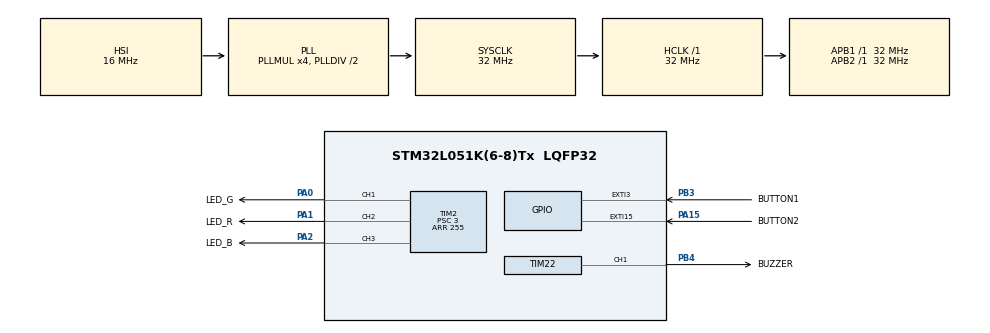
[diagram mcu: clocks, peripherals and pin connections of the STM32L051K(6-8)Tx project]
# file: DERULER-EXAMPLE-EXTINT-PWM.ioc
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Mcu.Family=STM32L0
Mcu.Name=STM32L051K(6-8)Tx
Mcu.Package=LQFP32
NVIC.EXTI2_3_IRQn=true\:0\:0\:false\:false\:true\:true\:true
NVIC.EXTI4_15_IRQn=true\:0\:0\:false\:false\:true\:true\:true
PA0.GPIO_Label=LED_G
PA0.Signal=S_TIM2_CH1
PA1.GPIO_Label=LED_R
PA1.Signal=S_TIM2_CH2
PA13.Mode=Serial_Wire
PA13.Signal=SYS_SWDIO
PA14.Mode=Serial_Wire
PA14.Signal=SYS_SWCLK
PA15.GPIO_Label=BUTTON2
PA15.GPIO_ModeDefaultEXTI=GPIO_MODE_IT_FALLING
PA15.GPIO_PuPd=GPIO_PULLUP
PA15.Signal=GPXTI15
PA2.GPIO_Label=LED_B
PA2.Signal=S_TIM2_CH3
PB3.GPIO_Label=BUTTON1
PB3.GPIO_ModeDefaultEXTI=GPIO_MODE_IT_FALLING
PB3.GPIO_PuPd=GPIO_PULLUP
PB3.Signal=GPXTI3
PB4.GPIO_Label=BUZZER
PB4.Signal=S_TIM22_CH1
ProjectManager.HeapSize=0x200
ProjectManager.StackSize=0x400
ProjectManager.TargetToolchain=STM32CubeIDE
RCC.AHBFreq_Value=32000000
RCC.APB1Freq_Value=32000000
RCC.APB1TimFreq_Value=32000000
RCC.APB2Freq_Value=32000000
RCC.APB2TimFreq_Value=32000000
RCC.HCLKFreq_Value=32000000
RCC.HSI16_VALUE=16000000
RCC.HSI_VALUE=16000000
RCC.LSE_VALUE=32768
RCC.MSI_VALUE=2097000
RCC.PLLMUL=RCC_PLLMUL_4
RCC.SYSCLKFreq_VALUE=32000000
RCC.SYSCLKSource=RCC_SYSCLKSOURCE_PLLCLK
RCC.VCOOutputFreq_Value=64000000
SH.S_TIM22_CH1.0=TIM22_CH1,PWM Generation1 CH1
SH.S_TIM2_CH1.0=TIM2_CH1,PWM Generation1 CH1
SH.S_TIM2_CH2.0=TIM2_CH2,PWM Generation2 CH2
SH.S_TIM2_CH3.0=TIM2_CH3,PWM Generation3 CH3
TIM2.Channel-PWM\ Generation1\ CH1=TIM_CHANNEL_1
TIM2.Channel-PWM\ Generation2\ CH2=TIM_CHANNEL_2
TIM2.Channel-PWM\ Generation3\ CH3=TIM_CHANNEL_3
TIM2.Period=255
TIM2.Prescaler=3
TIM22.Channel-PWM\ Generation1\ CH1=TIM_CHANNEL_1
TIM22.Period=99
TIM22.Prescaler=3199
TIM22.Pulse-PWM\ Generation1\ CH1=50
VP_TIM22_VS_ClockSourceINT.Mode=Internal
VP_TIM2_VS_ClockSourceINT.Mode=Internal
board=custom

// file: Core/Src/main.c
/* USER CODE BEGIN Header */
/**
  ******************************************************************************
  * @file           : main.c
  * @brief          : Main program body
  ******************************************************************************
  * @attention
  *
  * <h2><center>&copy; Copyright (c) 2021 STMicroelectronics.
  * All rights reserved.</center></h2>
  *
  * This software component is licensed by ST under BSD 3-Clause license,
  * the "License"; You may not use this file except in compliance with the
  * License. You may obtain a copy of the License at:
  *                        opensource.org/licenses/BSD-3-Clause
  *
  ******************************************************************************
  */

/**
 * DERULER-EXAMPLE-EXTINT-PWM (main.c)
 *
 * This examples shows how to use basic peripherals for external interrupts and pulse-width modulation (PWM) to improve our application.
 * Peripherals in a microcontroller are built-in hardware functions that can be used to off-load the processor. Instead of continuously reading
 * the value of the BUTTON1 and BUTTON2 pins in our code at some interval, we can get notified through an interrupt when the pin value has
 * changed due to the button being pressed. When an interrupt occurs the microcontroller will immediately stop working on what it was doing and
 * jump to the code we've written for what to do when the interrupt occurs. After this code has finished executing the microcontroller will go
 * back to doing what it was doing previously.
 *
 * By using the timer peripheral in PWM mode we can improve the RGB LED functionality by controlling the intensity of each color. This
 * lets us mix red, green and blue to create virtually any color.  In our application we set the timer to count from 0 to 255 (256 steps). Each
 * channel (color) can then be set to any value between 0-256 where 0 means fully off and 256 means fully on. With each color having 256
 * different intensities to select from we can create a total of 256 * 256 * 256 = 16.7M different colors. The 256 value is selected as it
 * represents 8 bits. This means we get 8-bit color per channel, or 24-bit total color information (8-bit * 3 colors, red + green + blue).
 * When BUTTON1 is pressed we start cycling between colors by adding or subtracting different amounts to the the different color. If the button
 * is pressed again we stop cycling the colors.
 *
 * In order to generate sound using the magnetic buzzer in our circuit we can also rely on a timer in PWM mode. By adjusting the timer
 * frequency and PWM duty cycle we can generate different sounds. In this example we configure the timer to generate a 100 Hz square wave signal
 * at 50% duty cycle which is activated when BUTTON2 is pressed. If the button is pressed again the frequency is doubled. If the frequency
 * reaches more than 20 KHz we stop the PWM output.
 *
 * Note1: The code for our main application is in this file (main.c). The code for handling interrupts is in stm32l0xx_it.c.
 * Note2: The audio frequenies we'll hear are: 100 Hz, 200 Hz, 400 Hz, 800 Hz, 1600 Hz, 3200 Hz, 6400 Hz, 12800 Hz
 *
 */

/* USER CODE END Header */
#include "main.h"

TIM_HandleTypeDef htim2;
TIM_HandleTypeDef htim22;

/* USER CODE BEGIN PV */

// RGB variables
int change_color = 0;
int red = 0;
int green = 0;
int blue = 0;
int red_add = 1;
int green_add = 2;
int blue_add = 3;

// Buzzer variables
int buzzer_active = 0;
int buzzer_frequency = 100;

/* USER CODE END PV */

void SystemClock_Config(void);
static void MX_GPIO_Init(void);
static void MX_TIM2_Init(void);
static void MX_TIM22_Init(void);

int main(void)
{

  /* MCU Configuration--------------------------------------------------------*/

  /* Reset of all peripherals, Initializes the Flash interface and the Systick. */
  HAL_Init();

  /* Configure the system clock */
  SystemClock_Config();

  /* Initialize all configured peripherals */
  MX_GPIO_Init();
  MX_TIM2_Init();
  MX_TIM22_Init();
  /* USER CODE BEGIN 2 */

  // Start PWM output of RGB LED channels
  HAL_TIM_PWM_Start(&htim2, TIM_CHANNEL_1);
  HAL_TIM_PWM_Start(&htim2, TIM_CHANNEL_2);
  HAL_TIM_PWM_Start(&htim2, TIM_CHANNEL_3);

  /* USER CODE END 2 */

  /* Infinite loop */
  while (1)
  {

	  // If change_color is 1, change color
	  if(change_color == 1) {

		  red += red_add; // Increase red by 1 each time, or decrease by 1 if max was reached
		  green += green_add; // Increase green by 2 each time, or decrease by 2 if max was reached
		  blue += blue_add; // Increase blue by 3 each time, or decrease by 3 if max was reached

		  // If any color value is more than 255 limit it to 256. If any color is less than 0, limit it to 0.
		  // Additionally change the sign of the value added to it each cycle to reverse the direction
		  if(red > 255) {
			  red = 256;
			  red_add = -red_add;
		  }
		  if(red < 0) {
			  red = 0;
			  red_add = -red_add;
		  }

		  if(green > 255) {
			  green = 256;
			  green_add = -green_add;
		  }
		  if(green < 0) {
			  green = 0;
			  green_add = -green_add;
		  }

		  if(blue > 255) {
			  blue = 256;
			  blue_add = -blue_add;
		  }
		  if(blue < 0) {
			  blue = 0;
			  blue_add = -blue_add;
		  }

		  // Apply color values to the corresponding PWM channel
		  __HAL_TIM_SET_COMPARE(&htim2, TIM_CHANNEL_2, red);
		  __HAL_TIM_SET_COMPARE(&htim2, TIM_CHANNEL_1, green);
		  __HAL_TIM_SET_COMPARE(&htim2, TIM_CHANNEL_3, blue);

		  // Wait for 10 ms before repeating
		  HAL_Delay(10);

	  }
  }
}

void SystemClock_Config(void)
{
  RCC_OscInitTypeDef RCC_OscInitStruct = {0};
  RCC_ClkInitTypeDef RCC_ClkInitStruct = {0};

  /** Configure the main internal regulator output voltage
  */
  __HAL_PWR_VOLTAGESCALING_CONFIG(PWR_REGULATOR_VOLTAGE_SCALE1);
  /** Initializes the RCC Oscillators according to the specified parameters
  * in the RCC_OscInitTypeDef structure.
  */
  RCC_OscInitStruct.OscillatorType = RCC_OSCILLATORTYPE_HSI;
  RCC_OscInitStruct.HSIState = RCC_HSI_ON;
  RCC_OscInitStruct.HSICalibrationValue = RCC_HSICALIBRATION_DEFAULT;
  RCC_OscInitStruct.PLL.PLLState = RCC_PLL_ON;
  RCC_OscInitStruct.PLL.PLLSource = RCC_PLLSOURCE_HSI;
  RCC_OscInitStruct.PLL.PLLMUL = RCC_PLLMUL_4;
  RCC_OscInitStruct.PLL.PLLDIV = RCC_PLLDIV_2;
  if (HAL_RCC_OscConfig(&RCC_OscInitStruct) != HAL_OK)
  {
    Error_Handler();
  }
  /** Initializes the CPU, AHB and APB buses clocks
  */
  RCC_ClkInitStruct.ClockType = RCC_CLOCKTYPE_HCLK|RCC_CLOCKTYPE_SYSCLK
                              |RCC_CLOCKTYPE_PCLK1|RCC_CLOCKTYPE_PCLK2;
  RCC_ClkInitStruct.SYSCLKSource = RCC_SYSCLKSOURCE_PLLCLK;
  RCC_ClkInitStruct.AHBCLKDivider = RCC_SYSCLK_DIV1;
  RCC_ClkInitStruct.APB1CLKDivider = RCC_HCLK_DIV1;
  RCC_ClkInitStruct.APB2CLKDivider = RCC_HCLK_DIV1;

  if (HAL_RCC_ClockConfig(&RCC_ClkInitStruct, FLASH_LATENCY_1) != HAL_OK)
  {
    Error_Handler();
  }
}

static void MX_TIM2_Init(void)
{

  TIM_ClockConfigTypeDef sClockSourceConfig = {0};
  TIM_MasterConfigTypeDef sMasterConfig = {0};
  TIM_OC_InitTypeDef sConfigOC = {0};

  htim2.Instance = TIM2;
  htim2.Init.Prescaler = 3;
  htim2.Init.CounterMode = TIM_COUNTERMODE_UP;
  htim2.Init.Period = 255;
  htim2.Init.ClockDivision = TIM_CLOCKDIVISION_DIV1;
  htim2.Init.AutoReloadPreload = TIM_AUTORELOAD_PRELOAD_DISABLE;
  if (HAL_TIM_Base_Init(&htim2) != HAL_OK)
  {
    Error_Handler();
  }
  sClockSourceConfig.ClockSource = TIM_CLOCKSOURCE_INTERNAL;
  if (HAL_TIM_ConfigClockSource(&htim2, &sClockSourceConfig) != HAL_OK)
  {
    Error_Handler();
  }
  if (HAL_TIM_PWM_Init(&htim2) != HAL_OK)
  {
    Error_Handler();
  }
  sMasterConfig.MasterOutputTrigger = TIM_TRGO_RESET;
  sMasterConfig.MasterSlaveMode = TIM_MASTERSLAVEMODE_DISABLE;
  if (HAL_TIMEx_MasterConfigSynchronization(&htim2, &sMasterConfig) != HAL_OK)
  {
    Error_Handler();
  }
  sConfigOC.OCMode = TIM_OCMODE_PWM1;
  sConfigOC.Pulse = 0;
  sConfigOC.OCPolarity = TIM_OCPOLARITY_HIGH;
  sConfigOC.OCFastMode = TIM_OCFAST_DISABLE;
  if (HAL_TIM_PWM_ConfigChannel(&htim2, &sConfigOC, TIM_CHANNEL_1) != HAL_OK)
  {
    Error_Handler();
  }
  if (HAL_TIM_PWM_ConfigChannel(&htim2, &sConfigOC, TIM_CHANNEL_2) != HAL_OK)
  {
    Error_Handler();
  }
  if (HAL_TIM_PWM_ConfigChannel(&htim2, &sConfigOC, TIM_CHANNEL_3) != HAL_OK)
  {
    Error_Handler();
  }
  HAL_TIM_MspPostInit(&htim2);

}

static void MX_TIM22_Init(void)
{

  TIM_ClockConfigTypeDef sClockSourceConfig = {0};
  TIM_MasterConfigTypeDef sMasterConfig = {0};
  TIM_OC_InitTypeDef sConfigOC = {0};

  htim22.Instance = TIM22;
  htim22.Init.Prescaler = 3199;
  htim22.Init.CounterMode = TIM_COUNTERMODE_UP;
  htim22.Init.Period = 99;
  htim22.Init.ClockDivision = TIM_CLOCKDIVISION_DIV1;
  htim22.Init.AutoReloadPreload = TIM_AUTORELOAD_PRELOAD_DISABLE;
  if (HAL_TIM_Base_Init(&htim22) != HAL_OK)
  {
    Error_Handler();
  }
  sClockSourceConfig.ClockSource = TIM_CLOCKSOURCE_INTERNAL;
  if (HAL_TIM_ConfigClockSource(&htim22, &sClockSourceConfig) != HAL_OK)
  {
    Error_Handler();
  }
  if (HAL_TIM_PWM_Init(&htim22) != HAL_OK)
  {
    Error_Handler();
  }
  sMasterConfig.MasterOutputTrigger = TIM_TRGO_RESET;
  sMasterConfig.MasterSlaveMode = TIM_MASTERSLAVEMODE_DISABLE;
  if (HAL_TIMEx_MasterConfigSynchronization(&htim22, &sMasterConfig) != HAL_OK)
  {
    Error_Handler();
  }
  sConfigOC.OCMode = TIM_OCMODE_PWM1;
  sConfigOC.Pulse = 50;
  sConfigOC.OCPolarity = TIM_OCPOLARITY_HIGH;
  sConfigOC.OCFastMode = TIM_OCFAST_DISABLE;
  if (HAL_TIM_PWM_ConfigChannel(&htim22, &sConfigOC, TIM_CHANNEL_1) != HAL_OK)
  {
    Error_Handler();
  }
  HAL_TIM_MspPostInit(&htim22);

}

static void MX_GPIO_Init(void)
{
  GPIO_InitTypeDef GPIO_InitStruct = {0};

  /* GPIO Ports Clock Enable */
  __HAL_RCC_GPIOA_CLK_ENABLE();
  __HAL_RCC_GPIOB_CLK_ENABLE();

  /*Configure GPIO pin : BUTTON2_Pin */
  GPIO_InitStruct.Pin = BUTTON2_Pin;
  GPIO_InitStruct.Mode = GPIO_MODE_IT_FALLING;
  GPIO_InitStruct.Pull = GPIO_PULLUP;
  HAL_GPIO_Init(BUTTON2_GPIO_Port, &GPIO_InitStruct);

  /*Configure GPIO pin : BUTTON1_Pin */
  GPIO_InitStruct.Pin = BUTTON1_Pin;
  GPIO_InitStruct.Mode = GPIO_MODE_IT_FALLING;
  GPIO_InitStruct.Pull = GPIO_PULLUP;
  HAL_GPIO_Init(BUTTON1_GPIO_Port, &GPIO_InitStruct);

  /* EXTI interrupt init*/
  HAL_NVIC_SetPriority(EXTI2_3_IRQn, 0, 0);
  HAL_NVIC_EnableIRQ(EXTI2_3_IRQn);

  HAL_NVIC_SetPriority(EXTI4_15_IRQn, 0, 0);
  HAL_NVIC_EnableIRQ(EXTI4_15_IRQn);

}

void Error_Handler(void)
{
  __disable_irq();
  while (1)
  {
  }
}

/************************ (C) COPYRIGHT STMicroelectronics *****END OF FILE****/
